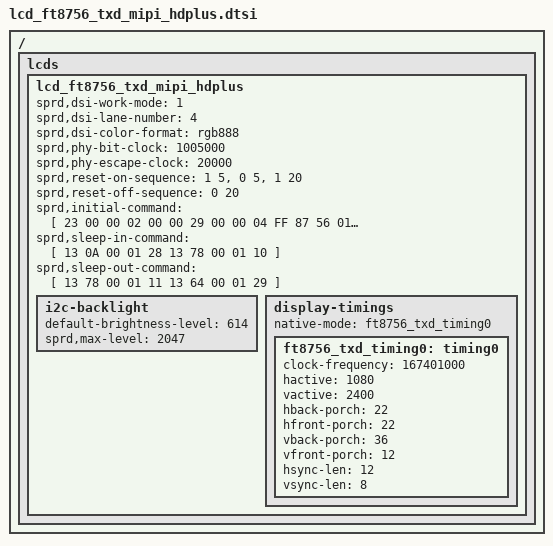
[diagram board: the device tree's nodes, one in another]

/*
 * G40396  LCD config dtsi file for spreadtrum
 *
 * Copyright (C) 2018, Spreadtrum Communications Inc.
 *
 * SPDX-License-Identifier: (GPL-2.0+ OR MIT)
 */

/ {
	fragment {
		target-path = "/";
		__overlay__ {
			lcds {
				lcd_ft8756_txd_mipi_hdplus: lcd_ft8756_txd_mipi_hdplus {

				    sprd,dsi-work-mode = <1>;
				    sprd,dsi-lane-number = <4>;
				    sprd,dsi-color-format = "rgb888";

				    sprd,phy-bit-clock = <1005000>;
				    sprd,phy-escape-clock = <20000>;/* kHz */

				    sprd,reset-on-sequence = <1 5>, <0 5>, <1 20>;
				    sprd,reset-off-sequence = <0 20>;
				    //sprd,use-dcs-write;
				    sprd,initial-command = [
					    23 00 00 02 00 00
					    29 00 00 04 FF 87 56 01
					    23 00 00 02 00 80
					    29 00 00 03 FF 87 56
					    //VCOM=-0.2V
					    23 00 00 02 00 00
					    29 00 00 03 D9 23 23
					    //Panel resulotion
					    23 00 00 02 00 A1
					    29 00 00 07 B3 04 38 09 60 00 FC
					    23 00 00 02 00 80
					    29 00 00 07 C0 00 8C 00 0C 00 2C
					    23 00 00 02 00 90
					    29 00 00 07 C0 00 8C 00 0C 00 2C
					    23 00 00 02 00 A0
					    29 00 00 07 C0 01 17 00 0C 00 2C
					    23 00 00 02 00 B0
					    29 00 00 06 C0 00 8C 00 0C 2C
					    23 00 00 02 00 C1
					    29 00 00 09 C0 00 CF 00 9D 00 8A 00 EC
					    23 00 00 02 00 D7
					    29 00 00 07 C0 00 8A 00 0C 00 2C
					    23 00 00 02 00 A3
					    29 00 00 07 C1 00 2C 00 2C 00 02
					    23 00 00 02 00 80
					    29 00 00 11 CE 01 81 09 13 00 D0 00 E8 00 8A 00 9A 00 68 00 74
					    23 00 00 02 00 90
					    29 00 00 10 CE 00 8E 0C DF 00 8E 80 09 13 00 04 00 28 27 1B
					    23 00 00 02 00 A0
					    29 00 00 04 CE 00 00 00
					    23 00 00 02 00 B0
					    29 00 00 04 CE 22 00 00
					    23 00 00 02 00 D1
					    29 00 00 08 CE 00 00 01 00 00 00 00
					    23 00 00 02 00 E1
					    29 00 00 0C CE 08 02 4D 02 4D 02 4D 00 00 00 00
					    23 00 00 02 00 F1
					    29 00 00 0A CE 13 09 0D 01 05 01 A5 00 D8
					    23 00 00 02 00 B0
					    29 00 00 05 CF 00 00 BF C3
					    23 00 00 02 00 B5
					    29 00 00 05 CF 04 04 E4 E8
					    23 00 00 02 00 C0
					    29 00 00 05 CF 09 09 2C 30
					    23 00 00 02 00 C5
					    29 00 00 05 CF 00 00 08 0C
					    23 00 00 02 00 E8
					    23 00 00 02 C0 40
					    23 00 00 02 00 80
					    29 00 00 05 c2 84 01 3F 3F
					    23 00 00 02 00 90
					    29 00 00 05 C2 02 01 00 00
					    23 00 00 02 00 A0
					    29 00 00 10 C2 84 04 00 00 8A 83 04 00 00 8A 82 04 00 00 8A
					    23 00 00 02 00 B0
					    29 00 00 06 C2 81 04 00 00 8A
					    23 00 00 02 00 E0
					    29 00 00 0F C2 33 33 33 33 33 33 00 00 12 00 05 02 00 00
					    23 00 00 02 00 C0
					    29 00 00 05 C3 99 99 99 99
					    23 00 00 02 00 D0
					    29 00 00 0D C3 45 00 00 05 45 00 00 05 45 00 00 05
					    23 00 00 02 00 80
					    29 00 00 11 CB C1 C1 00 C1 C1 00 00 C1 FE 01 C1 00 FD C1 00 C0
					    23 00 00 02 00 90
					    29 00 00 11 CB C0 00 00 00 00 00 00 00 FF 00 00 00 00 00 00 00
					    23 00 00 02 00 A0
					    29 00 00 05 CB 00 00 00 00
					    23 00 00 02 00 B0
					    29 00 00 05 CB 55 55 94 50
					    23 00 00 02 00 C0
					    29 00 00 05 CB 10 51 94 50
					    23 00 00 02 00 80
					    29 00 00 11 CC 00 00 00 25 25 29 16 17 18 19 1A 1B 22 24 06 06
					    23 00 00 02 00 90
					    29 00 00 09 CC 08 08 24 02 12 01 29 29
					    23 00 00 02 00 80
					    29 00 00 11 CD 00 00 00 25 25 29 16 17 18 19 1A 1B 22 24 07 07
					    23 00 00 02 00 90
					    29 00 00 09 CD 09 09 24 02 12 01 29 29
					    23 00 00 02 00 A0
					    29 00 00 11 CC 00 00 00 25 25 29 16 17 18 19 1A 1B 24 23 09 09
					    23 00 00 02 00 B0
					    29 00 00 09 CC 07 07 24 12 02 01 29 29
					    23 00 00 02 00 A0
					    29 00 00 11 CD 00 00 00 25 25 29 16 17 18 19 1A 1B 24 23 08 08
					    23 00 00 02 00 B0
					    29 00 00 09 CD 06 06 24 12 02 01 29 29
					    23 00 00 02 00 80
					    23 00 00 02 A7 10
					    23 00 00 02 00 A0
					    29 00 00 11 C3 35 02 41 35 53 14 20 00 00 00 13 50 24 42 05 31
					    23 00 00 02 00 82
					    29 00 00 03 A7 33 02
					    23 00 00 02 00 85
					    23 00 00 02 A7 00
					    //Reduce Source ring for COB
					    23 00 00 02 00 85
					    23 00 00 02 C4 1C
					    23 00 00 02 00 97
					    23 00 00 02 C4 01
					    //Source remapping
					    23 00 00 02 00 A0
					    29 00 00 04 C4 2D D2 2D
					    //VGH N_pump x2 (VGH=9.6V)
					    23 00 00 02 00 93
					    23 00 00 02 C5 29
					    //VGH I_pump x2 (VGH=9.6V)
					    23 00 00 02 00 97
					    23 00 00 02 C5 29
					    //VGL N_pump x2 (VGL=-9V)
					    23 00 00 02 00 9A
					    23 00 00 02 C5 23
					    //VGL I_pump x2 (VGL=-9V)
					    23 00 00 02 00 9C
					    23 00 00 02 C5 23
					    //VGHO1 (VGHO1=8.5V)
					    23 00 00 02 00 B6
					    29 00 00 03 C5 1E 1E
					    //VGLO1 (VGLO1=-8V)
					    23 00 00 02 00 B8
					    29 00 00 03 C5 1B 1B
					    23 00 00 02 00 9B
					    23 00 00 02 F5 4B
					    23 00 00 02 00 93
					    29 00 00 03 F5 00 00
					    23 00 00 02 00 9D
					    23 00 00 02 F5 49
					    23 00 00 02 00 82
					    29 00 00 03 F5 00 00
					    23 00 00 02 00 8C
					    29 00 00 04 C3 00 00 00
					    23 00 00 02 00 84
					    29 00 00 03 C5 28 28
					    23 00 00 02 00 A4
					    23 00 00 02 D7 00
					    23 00 00 02 00 80
					    29 00 00 03 F5 59 59
					    23 00 00 02 00 84
					    29 00 00 04 F5 59 59 59
					    23 00 00 02 00 96
					    23 00 00 02 F5 59
					    23 00 00 02 00 A6
					    23 00 00 02 F5 59
					    23 00 00 02 00 CA
					    23 00 00 02 C0 80
					    //GVDDP/N=+/-5.2V
					    23 00 00 02 00 00
					    29 00 00 03 D8 2F 2F
					    23 00 00 02 00 00
					    23 00 00 02 00 86 //Normal
					    29 00 00 07 C0 01 04 01 04 0D 03
					    23 00 00 02 00 96 //Idle
					    29 00 00 07 C0 01 04 01 04 0D 03
					    23 00 00 02 00 A6 //LPF
					    29 00 00 07 C0 01 04 01 04 18 03
					    23 00 00 02 00 E9 //Scaling
					    29 00 00 07 C0 01 04 01 04 0D 03
					    23 00 00 02 00 A3 //pre_dmy
					    29 00 00 07 CE 01 04 01 04 0D 03
					    23 00 00 02 00 B3 //pos_dmy
					    29 00 00 07 CE 01 04 01 04 0D 03
					    //Gamma value
					    23 00 00 02 00 00
					    29 00 00 29 E1 03 04 08 0F 7D 19 21 27 31 57 39 40 46 4C FD 50 59 61 68 F7 6F 77 7E 87 DF 91 97 9E A6 F5 AF BA C8 D1 5F DD EC F6 FC 7F
					    23 00 00 02 00 00
					    29 00 00 29 E2 03 04 08 0F 7D 19 21 27 31 57 39 40 46 4C FD 50 59 61 68 F7 6F 77 7E 87 DF 91 97 9E A6 F5 AF BA C8 D1 5F DD EC F6 FC 7F
					    23 00 00 02 00 00
					    29 00 00 29 E3 03 04 08 0F 7D 19 21 27 31 57 39 40 46 4C FD 50 59 61 68 F7 6F 77 7E 87 DF 91 97 9E A6 F5 AF BA C8 D1 5F DD EC F6 FC 7F
					    23 00 00 02 00 00
					    29 00 00 29 E4 03 04 08 0F 7D 19 21 27 31 57 39 40 46 4C FD 50 59 61 68 F7 6F 77 7E 87 DF 91 97 9E A6 F5 AF BA C8 D1 5F DD EC F6 FC 7F
					    23 00 00 02 00 00
					    29 00 00 29 E5 03 04 08 0F 7D 19 21 27 31 57 39 40 46 4C FD 50 59 61 68 F7 6F 77 7E 87 DF 91 97 9E A6 F5 AF BA C8 D1 5F DD EC F6 FC 7F
					    23 00 00 02 00 00
					    29 00 00 29 E6 03 04 08 0F 7D 19 21 27 31 57 39 40 46 4C FD 50 59 61 68 F7 6F 77 7E 87 DF 91 97 9E A6 F5 AF BA C8 D1 5F DD EC F6 FC 7F
					    23 00 00 02 00 CC
					    23 00 00 02 C0 10
					    23 00 00 02 00 b3
					    23 00 00 02 C5 D1
					    // CABC
					    23 00 00 02 00 80
					    29 00 00 0D CA CE BB AB 9F 96 8E 87 82 80 80 80 80
					    23 00 00 02 00 90
					    29 00 00 0A CA FD FF EA FC FF CC FA FF 66
					    23 00 00 02 00 00
					    29 00 00 04 FF FF FF FF
					    29 00 00 03 51 ff 0f
					    23 00 00 02 53 2c
					    23 00 00 02 55 02
					    05 78 00 01 11
					    05 78 00 01 29
					    23 FF 00 02 35 00
					    ];

				    sprd,sleep-in-command = [
					    13 0A 00 01 28
					    13 78 00 01 10
					    ];
				    sprd,sleep-out-command = [
					    13 78 00 01 11
					    13 64 00 01 29
					    ];

				    i2c-backlight {
					    default-brightness-level = <614>;
					    sprd,max-level = <2047>;
				    };

				    display-timings {
					native-mode = <&ft8756_txd_timing0>;

					ft8756_txd_timing0: timing0 {
					    clock-frequency = <167401000>;
					    hactive = <1080>;
					    vactive = <2400>;
					    hback-porch = <22>;
					    hfront-porch = <22>;
					    vback-porch = <36>;
					    vfront-porch = <12>;
					    hsync-len = <12>;
					    vsync-len = <8>;
					};
				    };
			    };
			};
		};
	};
};
